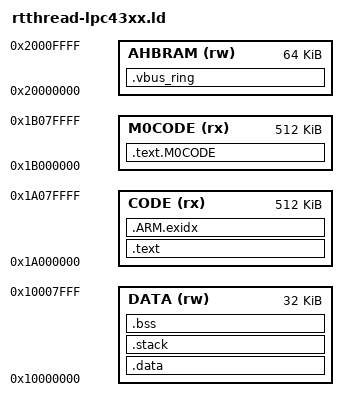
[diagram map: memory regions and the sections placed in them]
/*
 * linker script for LPC43xx SPIFI (4Mb NorFlash, 32kB SRAM ) with GNU ld
 * yiyue.fang 2012-04-14
 */

/* Program Entry, set to mark it as "used" and avoid gc */
MEMORY
{
    CODE (rx) : ORIGIN = 0x1A000000, LENGTH = 0x00080000
    M0CODE (rx) : ORIGIN = 0x1B000000, LENGTH = 0x00080000
    DATA (rw) : ORIGIN = 0x10000000, LENGTH = 0x00008000
    AHBRAM (rw) : ORIGIN = 0x20000000, LENGTH = 0x00010000
}
ENTRY(Reset_Handler)
_system_stack_size = 0x200;

SECTIONS
{
    .text :
    {
        . = ALIGN(4);
        KEEP(*(.interrupt_vector))      /* Startup code */
        . = ALIGN(4);
        *(.text)                        /* remaining code */
        *(.text.*)                      /* remaining code */
        *(.rodata)                      /* read-only data (constants) */
        *(.rodata*)
        *(.glue_7)
        *(.glue_7t)
        *(.gnu.linkonce.t*)

        /* section information for finsh shell */
        . = ALIGN(4);
        __fsymtab_start = .;
        KEEP(*(FSymTab))
        __fsymtab_end = .;
        . = ALIGN(4);
        __vsymtab_start = .;
        KEEP(*(VSymTab))
        __vsymtab_end = .;
        . = ALIGN(4);

        . = ALIGN(4);
        _etext = .;
    } > CODE = 0

    /* .ARM.exidx is sorted, so has to go in its own output section.  */
    __exidx_start = .;
    .ARM.exidx :
    {
        *(.ARM.exidx* .gnu.linkonce.armexidx.*)

        /* This is used by the startup in order to initialize the .data secion */
        _sidata = .;
    } > CODE
    __exidx_end = .;

    /* .data section which is used for initialized data */

    .data : AT (_sidata)
    {
        . = ALIGN(4);
        /* This is used by the startup in order to initialize the .data secion */
        _sdata = . ;

        *(.data)
        *(.data.*)
        *(.gnu.linkonce.d*)

        . = ALIGN(4);
        /* This is used by the startup in order to initialize the .data secion */
        _edata = . ;
    } >DATA

    . = _edata  ;
    .stack :
    {
        . = . + _system_stack_size;
        . = ALIGN(4);
        _estack = .;
    } >DATA

    __bss_start = .;
    .bss :
    {
        . = ALIGN(4);
        /* This is used by the startup in order to initialize the .bss secion */
        _sbss = .;

        *(.bss)
        *(.bss.*)
        *(COMMON)

        . = ALIGN(4);
        /* This is used by the startup in order to initialize the .bss secion */
        _ebss = . ;        
        *(.bss.init)
    } > DATA
    __bss_end = .;

    .vbus_ring (NOLOAD) :
    {
        *(vbus_ring)
    } > AHBRAM


    .text.M0CODE :
    {
        *(M0_CODE)
    } > M0CODE = 0

    _end = .;

    /* Stabs debugging sections.  */
    .stab          0 : { *(.stab) }
    .stabstr       0 : { *(.stabstr) }
    .stab.excl     0 : { *(.stab.excl) }
    .stab.exclstr  0 : { *(.stab.exclstr) }
    .stab.index    0 : { *(.stab.index) }
    .stab.indexstr 0 : { *(.stab.indexstr) }
    .comment       0 : { *(.comment) }
    /* DWARF debug sections.
     * Symbols in the DWARF debugging sections are relative to the beginning
     * of the section so we begin them at 0.  */
    /* DWARF 1 */
    .debug          0 : { *(.debug) }
    .line           0 : { *(.line) }
    /* GNU DWARF 1 extensions */
    .debug_srcinfo  0 : { *(.debug_srcinfo) }
    .debug_sfnames  0 : { *(.debug_sfnames) }
    /* DWARF 1.1 and DWARF 2 */
    .debug_aranges  0 : { *(.debug_aranges) }
    .debug_pubnames 0 : { *(.debug_pubnames) }
    /* DWARF 2 */
    .debug_info     0 : { *(.debug_info .gnu.linkonce.wi.*) }
    .debug_abbrev   0 : { *(.debug_abbrev) }
    .debug_line     0 : { *(.debug_line) }
    .debug_frame    0 : { *(.debug_frame) }
    .debug_str      0 : { *(.debug_str) }
    .debug_loc      0 : { *(.debug_loc) }
    .debug_macinfo  0 : { *(.debug_macinfo) }
    /* SGI/MIPS DWARF 2 extensions */
    .debug_weaknames 0 : { *(.debug_weaknames) }
    .debug_funcnames 0 : { *(.debug_funcnames) }
    .debug_typenames 0 : { *(.debug_typenames) }
    .debug_varnames  0 : { *(.debug_varnames) }
}
